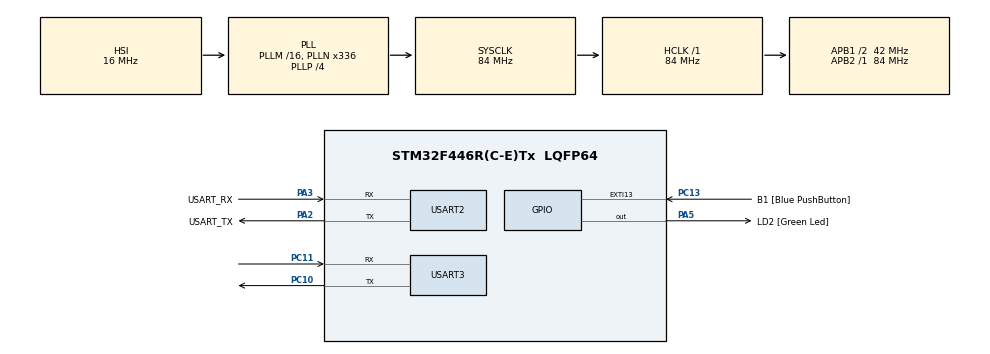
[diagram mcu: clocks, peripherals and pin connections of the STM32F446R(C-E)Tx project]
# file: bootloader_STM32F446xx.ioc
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Mcu.Family=STM32F4
Mcu.Name=STM32F446R(C-E)Tx
Mcu.Package=LQFP64
NVIC.PriorityGroup=NVIC_PRIORITYGROUP_0
PA13.GPIO_Label=TMS
PA13.Mode=Serial_Wire
PA13.Signal=SYS_JTMS-SWDIO
PA14.GPIO_Label=TCK
PA14.Mode=Serial_Wire
PA14.Signal=SYS_JTCK-SWCLK
PA2.GPIO_Label=USART_TX
PA2.Mode=Asynchronous
PA2.Signal=USART2_TX
PA3.GPIO_Label=USART_RX
PA3.Mode=Asynchronous
PA3.Signal=USART2_RX
PA5.GPIO_Label=LD2 [Green Led]
PA5.Signal=GPIO_Output
PB3.GPIO_Label=SWO
PB3.Signal=SYS_JTDO-SWO
PC10.Mode=Asynchronous
PC10.Signal=USART3_TX
PC11.Mode=Asynchronous
PC11.Signal=USART3_RX
PC13.GPIO_Label=B1 [Blue PushButton]
PC13.GPIO_ModeDefaultEXTI=GPIO_MODE_IT_FALLING
PC13.Signal=GPXTI13
PC14-OSC32_IN.Signal=RCC_OSC32_IN
PC15-OSC32_OUT.Signal=RCC_OSC32_OUT
PH0-OSC_IN.Signal=RCC_OSC_IN
PH1-OSC_OUT.Signal=RCC_OSC_OUT
ProjectManager.HeapSize=0x200
ProjectManager.StackSize=0x400
ProjectManager.TargetToolchain=MDK-ARM V5.32
RCC.48MHZClocksFreq_Value=84000000
RCC.AHBFreq_Value=84000000
RCC.APB1CLKDivider=RCC_HCLK_DIV2
RCC.APB1Freq_Value=42000000
RCC.APB1TimFreq_Value=84000000
RCC.APB2Freq_Value=84000000
RCC.APB2TimFreq_Value=84000000
RCC.CortexFreq_Value=84000000
RCC.FLatency-AdvancedSettings=FLASH_LATENCY_2
RCC.HCLKFreq_Value=84000000
RCC.HSE_VALUE=8000000
RCC.HSI_VALUE=16000000
RCC.PLLN=336
RCC.PLLP=RCC_PLLP_DIV4
RCC.SYSCLKFreq_VALUE=84000000
RCC.SYSCLKSource=RCC_SYSCLKSOURCE_PLLCLK
RCC.USBFreq_Value=168000000
RCC.VCOOutputFreq_Value=336000000
USART2.VirtualMode=VM_ASYNC
USART3.VirtualMode=VM_ASYNC
VP_CRC_VS_CRC.Mode=CRC_Activate
board=NUCLEO-F446RE

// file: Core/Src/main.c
/* USER CODE BEGIN Header */
/**
  ******************************************************************************
  * @file           : main.c
  * @brief          : Main program body
  ******************************************************************************
  * @attention
  *
  * Copyright (c) 2025 STMicroelectronics.
  * All rights reserved.
  *
  * This software is licensed under terms that can be found in the LICENSE file
  * in the root directory of this software component.
  * If no LICENSE file comes with this software, it is provided AS-IS.
  *
  ******************************************************************************
  */
/* USER CODE END Header */
#include "main.h"
#include "stm32f4xx_hal.h"
#include <stdio.h>
#include <stdarg.h>
#include <string.h>

/* USER CODE BEGIN Includes */
//debug
#define BL_DEBUG_MSG_EN

/* USER CODE END Includes */

CRC_HandleTypeDef hcrc;

UART_HandleTypeDef huart2;
UART_HandleTypeDef huart3;

#define D_UART &huart2
#define C_UART &huart3

void SystemClock_Config(void);
static void MX_GPIO_Init(void);
static void MX_USART2_UART_Init(void);
static void MX_CRC_Init(void);
static void MX_USART3_UART_Init(void);

/* USER CODE BEGIN PFP */
static void printmsg(char *format,...);
/* USER CODE END PFP */

	char data_tx2[] = "Hello from UART2\r\n";
	char data_tx3[] = "Hello from UART3\r\n";
int main(void)
{

  /* MCU Configuration--------------------------------------------------------*/

  /* Reset of all peripherals, Initializes the Flash interface and the Systick. */
  HAL_Init();

  /* Configure the system clock */
  SystemClock_Config();

  /* Initialize all configured peripherals */
  MX_GPIO_Init();

  MX_CRC_Init();
	MX_USART2_UART_Init();
  MX_USART3_UART_Init();
  /* USER CODE BEGIN 2 */

	if ( HAL_GPIO_ReadPin(B1_GPIO_Port,B1_Pin) == GPIO_PIN_RESET )
	{
		printmsg("BL_DEBUG_MESSAGE:Button is pressed. Going to BL mode\r\n");
		bootloader_uart_read_data();
	}
	else
	{
		printmsg("BL_DEBUG_MESSAGE:Button is not pressed. Going to user app\r\n");
		bootloader_jump_to_user_app();
	}

  /* USER CODE END 2 */

  /* Infinite loop */
  while (1)
  {
		uint32_t current_tick = HAL_GetTick();

		while(HAL_GetTick() < current_tick + 500) {};
  }
}

void bootloader_uart_read_data()
{
}
/*
This function implements handling the control over to the user application
*/
void bootloader_jump_to_user_app()
{
	void (*app_reset_handler)(void);

	printmsg("BL_DEBUG_MSG:bootloader_jump_to_user_app");

	//1 Configure the MSP by reading the balue from the base address of the sector 2
	uint32_t msp_value = *(volatile uint32_t *) FLASH_SECTOR2_BASE_ADDRESS;
	printmsg("BL_DEBUG_MSG:MSP value :%#x\n",msp_value);

	//set main stack pointer
	__set_MSP(msp_value);

	uint32_t resethandler_address = *(volatile uint32_t *) (FLASH_SECTOR2_BASE_ADDRESS + 4);
	app_reset_handler = (void*) resethandler_address;

	printmsg("BL_DEBUG_MSG:app reset handler addr:%#x\n",app_reset_handler);

	app_reset_handler();
}

void printmsg(char *format,...)
{
#ifdef BL_DEBUG_MSG_EN
		char str[80];

	va_list args;
	va_start(args, format);
	vsnprintf(str, sizeof(str), format, args);
	HAL_UART_Transmit(D_UART, (uint8_t *)str, strlen(str), HAL_MAX_DELAY);
	va_end(args);
#endif
}

void SystemClock_Config(void)
{
  RCC_OscInitTypeDef RCC_OscInitStruct = {0};
  RCC_ClkInitTypeDef RCC_ClkInitStruct = {0};

  /** Configure the main internal regulator output voltage
  */
  __HAL_RCC_PWR_CLK_ENABLE();
  __HAL_PWR_VOLTAGESCALING_CONFIG(PWR_REGULATOR_VOLTAGE_SCALE3);

  /** Initializes the RCC Oscillators according to the specified parameters
  * in the RCC_OscInitTypeDef structure.
  */
  RCC_OscInitStruct.OscillatorType = RCC_OSCILLATORTYPE_HSI;
  RCC_OscInitStruct.HSIState = RCC_HSI_ON;
  RCC_OscInitStruct.HSICalibrationValue = RCC_HSICALIBRATION_DEFAULT;
  RCC_OscInitStruct.PLL.PLLState = RCC_PLL_ON;
  RCC_OscInitStruct.PLL.PLLSource = RCC_PLLSOURCE_HSI;
  RCC_OscInitStruct.PLL.PLLM = 16;
  RCC_OscInitStruct.PLL.PLLN = 336;
  RCC_OscInitStruct.PLL.PLLP = RCC_PLLP_DIV4;
  RCC_OscInitStruct.PLL.PLLQ = 2;
  RCC_OscInitStruct.PLL.PLLR = 2;
  if (HAL_RCC_OscConfig(&RCC_OscInitStruct) != HAL_OK)
  {
    Error_Handler();
  }

  /** Initializes the CPU, AHB and APB buses clocks
  */
  RCC_ClkInitStruct.ClockType = RCC_CLOCKTYPE_HCLK|RCC_CLOCKTYPE_SYSCLK
                              |RCC_CLOCKTYPE_PCLK1|RCC_CLOCKTYPE_PCLK2;
  RCC_ClkInitStruct.SYSCLKSource = RCC_SYSCLKSOURCE_PLLCLK;
  RCC_ClkInitStruct.AHBCLKDivider = RCC_SYSCLK_DIV1;
  RCC_ClkInitStruct.APB1CLKDivider = RCC_HCLK_DIV2;
  RCC_ClkInitStruct.APB2CLKDivider = RCC_HCLK_DIV1;

  if (HAL_RCC_ClockConfig(&RCC_ClkInitStruct, FLASH_LATENCY_2) != HAL_OK)
  {
    Error_Handler();
  }
}

static void MX_CRC_Init(void)
{

  hcrc.Instance = CRC;
  if (HAL_CRC_Init(&hcrc) != HAL_OK)
  {
    Error_Handler();
  }

}

static void MX_USART2_UART_Init(void)
{

  huart2.Instance = USART2;
  huart2.Init.BaudRate = 115200;
  huart2.Init.WordLength = UART_WORDLENGTH_8B;
  huart2.Init.StopBits = UART_STOPBITS_1;
  huart2.Init.Parity = UART_PARITY_NONE;
  huart2.Init.Mode = UART_MODE_TX_RX;
  huart2.Init.HwFlowCtl = UART_HWCONTROL_NONE;
  huart2.Init.OverSampling = UART_OVERSAMPLING_16;
  if (HAL_UART_Init(&huart2) != HAL_OK)
  {
    Error_Handler();
  }

}

static void MX_USART3_UART_Init(void)
{

  huart3.Instance = USART3;
  huart3.Init.BaudRate = 115200;
  huart3.Init.WordLength = UART_WORDLENGTH_8B;
  huart3.Init.StopBits = UART_STOPBITS_1;
  huart3.Init.Parity = UART_PARITY_NONE;
  huart3.Init.Mode = UART_MODE_TX_RX;
  huart3.Init.HwFlowCtl = UART_HWCONTROL_NONE;
  huart3.Init.OverSampling = UART_OVERSAMPLING_16;
  if (HAL_UART_Init(&huart3) != HAL_OK)
  {
    Error_Handler();
  }

}

static void MX_GPIO_Init(void)
{
  GPIO_InitTypeDef GPIO_InitStruct = {0};

  /* GPIO Ports Clock Enable */
  __HAL_RCC_GPIOC_CLK_ENABLE();
  __HAL_RCC_GPIOH_CLK_ENABLE();
  __HAL_RCC_GPIOA_CLK_ENABLE();
  __HAL_RCC_GPIOB_CLK_ENABLE();

  /*Configure GPIO pin Output Level */
  HAL_GPIO_WritePin(LD2_GPIO_Port, LD2_Pin, GPIO_PIN_RESET);

  /*Configure GPIO pin : B1_Pin */
  GPIO_InitStruct.Pin = B1_Pin;
  GPIO_InitStruct.Mode = GPIO_MODE_IT_FALLING;
  GPIO_InitStruct.Pull = GPIO_NOPULL;
  HAL_GPIO_Init(B1_GPIO_Port, &GPIO_InitStruct);

  /*Configure GPIO pin : LD2_Pin */
  GPIO_InitStruct.Pin = LD2_Pin;
  GPIO_InitStruct.Mode = GPIO_MODE_OUTPUT_PP;
  GPIO_InitStruct.Pull = GPIO_NOPULL;
  GPIO_InitStruct.Speed = GPIO_SPEED_FREQ_LOW;
  HAL_GPIO_Init(LD2_GPIO_Port, &GPIO_InitStruct);

}

void Error_Handler(void)
{
  __disable_irq();
  while (1)
  {
  }
}
